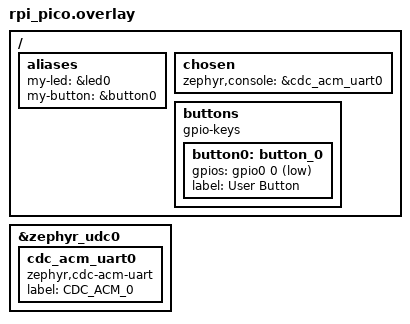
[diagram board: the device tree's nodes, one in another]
/ {
    aliases{
        my-led = &led0;
        my-button = &button0;
    };

    chosen{
        zephyr,console = &cdc_acm_uart0;
    };

    buttons {
        compatible = "gpio-keys";
        
        button0: button_0 {
            gpios = <&gpio0 0 (GPIO_ACTIVE_LOW | GPIO_PULL_UP)>;
            label = "User Button";
        };
    };
};


&zephyr_udc0 {
    cdc_acm_uart0: cdc_acm_uart0 {
        compatible = "zephyr,cdc-acm-uart";
        label = "CDC_ACM_0";
    };
};
